# STM32U5F7 register map
File version: 1.1
CPU: CM33 r0p1, little endian, MPU, FPU, 4 interrupt priority bits
Registers are 32-bit, read-write, reset 0x0 unless marked. A register's access mark holds for its fields unless they carry their own. Offsets are from the block's base; [hi:lo] are bit positions; {n}, {i} and the like mark numbered series.

## LPDMA1
Base 0x46025000
Same registers: SEC_LPDMA1 0x56025000
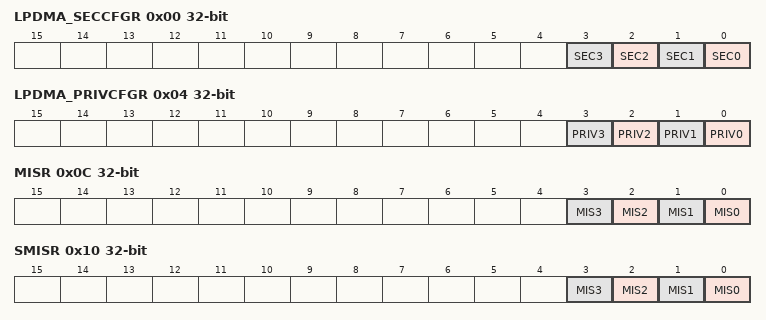
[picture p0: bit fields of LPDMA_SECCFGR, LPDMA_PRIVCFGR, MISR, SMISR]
0x00 LPDMA_SECCFGR — LPDMA secure configuration register
  [n] SEC{n} (n=0..3)
0x04 LPDMA_PRIVCFGR — LPDMA privileged configuration register
  [n] PRIV{n} (n=0..3)
0x0C MISR ro — LPDMA non-secure masked interrupt status register
  [n] MIS{n} (n=0..3)
0x10 SMISR ro — LPDMA secure masked interrupt status register
  [n] MIS{n} (n=0..3)
{0x50+0x80*i} LPDMA_C{i}LBAR (i=0..3) — channel x linked-list base address register
  [31:16] LBA — linked-list base address of DMA channel x
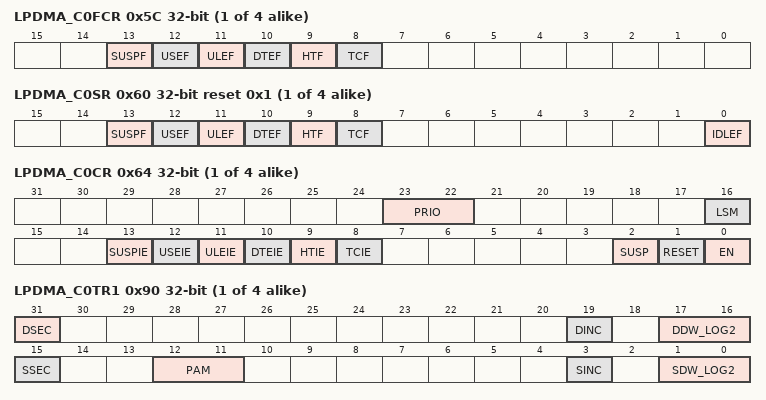
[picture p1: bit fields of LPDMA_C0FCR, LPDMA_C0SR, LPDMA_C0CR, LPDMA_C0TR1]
{0x5C+0x80*i} LPDMA_C{i}FCR wo (i=0..3) — LPDMA channel x flag clear register
  [13] SUSPF — completed suspension flag clear - 0: no effect - 1: clears the corresponding SUSPF flag
  [12] USEF — user setting error flag clear - 0: no effect - 1: clears the corresponding USEF flag
  [11] ULEF — update link transfer error flag clear - 0: no effect - 1: clears the corresponding ULEF flag
  [10] DTEF — data transfer error flag clear - 0: no effect - 1: clears the corresponding DTEF flag
  [9] HTF — half transfer flag clear - 0: no effect - 1: clears the corresponding HTF flag
  [8] TCF — transfer complete flag clear - 0: no effect - 1: clears the corresponding TCF flag
{0x60+0x80*i} LPDMA_C{i}SR ro reset 0x1 (i=0..3) — channel x status register
  [13] SUSPF — completed suspension flag - 0: no completed suspension event - 1: a completed suspension event occurred
  [12] USEF — user setting error flag - 0: no user setting error event - 1: a user setting error event occurred
  [11] ULEF — update link transfer error flag - 0: no update link transfer error event - 1: a master bus error event occurred while updating a linked-list register from memory
  [10] DTEF — data transfer error flag - 0: no data transfer error event - 1: a master bus error event occurred on a data transfer
  [9] HTF — half transfer flag - 0: no half transfer event - 1: an half transfer event occurred An half transfer event is either an half block transfer or an half 2D/repeated block transfer, depending on the transfer complete event mode i.e. LPDMA_CxTR2.TCEM[1:0]. An half block transfer occurs when half of the bytes of the source block size (i.e. rounded up integer of LPDMA_CxBR1.BNDT[15:0]/2) has been transferred to the destination. Half 2D/repeated block transfer occurs when half of the repeated blocks (i.e. rounded up integer of (LPDMA_CxBR1.BRC[10:0]+1)/2) have been transferred to the destination.
  [8] TCF — transfer complete flag - 0: no transfer complete event - 1: a transfer complete event occurred A transfer complete event is either a block transfer complete or a 2D/repeated block transfer complete, or a LLI transfer complete including the upload of the next LLI if any, or the full linked-list completion, depending on the transfer complete event mode i.e. LPDMA_CxTR2.TCEM[1:0].
  [0] IDLEF — idle flag - 0: the channel is not in idle state - 1: the channel is in idle state This idle flag is de-asserted by hardware when the channel is enabled (i.e. is written 1 into LPDMA_CxCR.EN) with a valid channel configuration (i.e. no USEF to be immediately reported). This idle flag is asserted after hard reset or by hardware when the channel is back in idle state (i.e. in suspended or disabled state).
{0x64+0x80*i} LPDMA_C{i}CR (i=0..3) — channel x control register
  [23:22] PRIO — priority level of the DMA transfer of the channel x vs others- 00: low priority, low weight- 01: low priority, mid weight- 10: low priority, high weight- 11: high priorityNote: This bit must be written when EN=0. This bit is read-only when EN=1.
  [16] LSM — Link Step mode:- 0: channel is executed for the full linked-list, and completed at the end (if any) of the last LLI i.e. when LPDMA_CxLLR=0: the 16 low significant bits of the link address are null (LA[15:0]=0) and all the update bits are null i.e. UT1=UB1=UT2=USA=UDA=UB2 =UT3=ULL=0. Then LPDMA_CxBR1.BRC[10:0]=0 and LPDMA_CxBR1.BNDT[15:0]=0.- 1: channel is executed once for the current LLI:* First the (possibly 2D/repeated) block transfer is executed as defined by the current internal register file until that (LPDMA_CxBR1.BRC[10:0]=0 and LPDMA_CxBR1.BNDT[15:0]=0).* Secondly the next linked-list data structure is conditionally uploaded from memory as defined by LPDMA_CxLLR register. Then channel execution is completed.Note: This bit must be written when EN=0. This bit is read-only when EN=1.
  [13] SUSPIE — completed suspension interrupt enable - 0: interrupt disabled - 1: interrupt enabled
  [12] USEIE — user setting error interrupt enable - 0: interrupt disabled - 1: interrupt enabled
  [11] ULEIE — update link transfer error interrupt enable - 0: interrupt disabled - 1: interrupt enabled
  [10] DTEIE — data transfer error interrupt enable - 0: interrupt disabled - 1: interrupt enabled
  [9] HTIE — half transfer complete interrupt enable - 0: interrupt disabled - 1: interrupt enabled
  [8] TCIE — transfer complete interrupt enable - 0: interrupt disabled - 1: interrupt enabled
  [2] SUSP — suspend - 0: write: resume channel, read: channel not suspended - 1: write: suspend channel, read: channel suspended Writing 1 into the field RESET (bit 1) causes the hardware to de-assert this bit, whatever is written into this bit 2. Else: Software must write 1 in order to suspend an active channel i.e. a channel with an on-going DMA transfer over its master ports. Software must write 0 in order to resume a suspended channel, following the programming sequence in Figure 3: DMA channel suspend and resume sequence.
  [1] RESET — reset - 0: no channel reset - 1: channel reset This bit is write only. Writing 0 has no impact. Writing 1 implies/will imply the reset of the FIFO, the reset of the channel internal state, and the reset of the SUSP and EN bits, whatever is written in respectively bit 2 and bit 0. The reset is/will be effective when the channel is in state i.e. either i) the active channel is in suspended state (i.e. LPDMA_CxSR.SUSPF=1 and LPDMA_CxSR.IDLEF=1 and LPDMA_CxCR.EN=1) or ii) the channel is in disabled state (i.e. LPDMA_CxSR.IDLEF=1 and LPDMA_CxCR.EN=0). After writing a RESET, if the user wants to continue using this channel, the user should explicitly reconfigure the channel including the hardware-modified configuration registers LPDMA_CxBR1, LPDMA_CxSAR and LPDMA_CxDAR, before enabling again the channel. Following the programming sequence in Figure 4: DMA channel abort and restart sequence.
  [0] EN — enable - 0: write: ignored, read: channel disabled - 1: write: enable channel, read: channel enabled Writing 1 into the field RESET (bit 1) causes the hardware to de-assert this bit, whatever is written into this bit 0. Else: * this bit is de-asserted by hardware when there is a transfer error (master bus error or user setting error) or when there is a channel transfer complete (channel ready to be configured, e.g. if LSM=1 at the end of a single execution of the LLI). * Else, this bit can be asserted by software. Writing 0 into this EN bit is ignored.
{0x90+0x80*i} LPDMA_C{i}TR1 (i=0..3) — LPDMA channel x transfer register 1
  [31] DSEC — security attribute of the DMA transfer to the destinationThis is a secure register bit.This bit can only be read by a secure software. This bit must be written by a secure software when LPDMA_SECCFGR.SECx=1. A secure write is ignored when LPDMA_SECCFGR.SECx=0.When is de-asserted LPDMA_SECCFGR.SECx, this bit is also de-asserted by hardware (on a secure reconfiguration of the channel as non-secure), and the DMA transfer to the destination is non-secure.If LPDMA_SECCFGR.SECx=1 (and a secure access):- 0: non-secure- 1: secure
  [19] DINC — destination incrementing burst- 0: fixed burst- 1: contiguously incremented burstThe destination address, pointed by DMA_CxDAR, is either kept constant after a burst beat/single transfer, or is incremented by the offset value corresponding to a contiguous data after a burst beat/single transfer.
  [17:16] DDW_LOG2 — binary logarithm of the destination data width of a burst, in bytes- 00: byte- 01: half-word (2 bytes)- 10: word (4 bytes)- 11: a user setting error is reported and no transfer is issued.Note: Setting a 8-byte data width is causing a user setting error to be reported and none transfer is issued.Note: A destination burst transfer must have an aligned address with its data width (c.f. start address LPDMA_CxDAR[2:0] and address offset LPDMA_CxTR3.DAO[2:0] vs DDW_LOG2[1:0]). Else a user setting error is reported and none transfer is issued.Note: When configured in packing mode (i.e. if PAM[1]=1 and destination data width different from source data width), a source block size must be a multiple of the destination data width (c.f. LPDMA_CxBR1.BNDT[2:0] vs DDW_LOG2[1:0]). Else a user setting error is reported and none transfer is issued.
  [15] SSEC — security attribute of the DMA transfer from the sourceThis is a secure register bit.This bit can only be read by a secure software. This bit must be written by a secure software when LPDMA_SECCFGR.SECx=1. A secure write is ignored when LPDMA_SECCFGR.SECx=0.When is de-asserted LPDMA_SECCFGR.SECx, this bit is also de-asserted by hardware (on a secure reconfiguration of the channel as non-secure), and the DMA transfer from the source is non-secure.If LPDMA_SECCFGR.SECx=1 (and a secure access):- 0: non-secure- 1: secure
  [12:11] PAM
  [3] SINC — source incrementing burst- 0: fixed burst- 1: contiguously incremented burstThe source address, pointed by DMA_CxSAR, is either kept constant after a burst beat/single transfer, or is incremented by the offset value corresponding to a contiguous data after a burst beat/single transfer.
  [1:0] SDW_LOG2 — binary logarithm of the source data width of a burst, in bytes- 00: byte- 01: half-word (2 bytes)- 10: word (4 bytes)- 11: a user setting error is reported and no transfer is issued.Note: Setting a 8-byte data width is causing a user setting error to be reported and none transfer is issued.Note: a source block size must be a multiple of the source data width (c.f. LPDMA_CxBR1.BNDT[2:0] vs SDW_LOG2[1:0]). Else a user setting error is reported and none transfer is issued.Note: A source burst transfer must have an aligned address with its data width (c.f. start address LPDMA_CxSAR[2:0] and address offset LPDMA_CxTR3.SAO[2:0] vs SDW_LOG2[1:0]). Else a user setting error is reported and none transfer is issued.
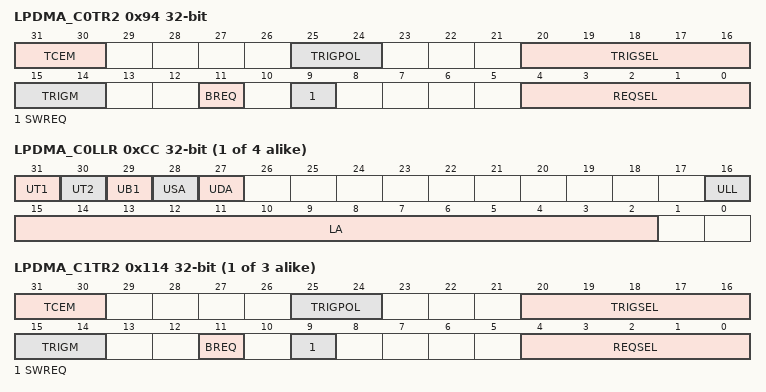
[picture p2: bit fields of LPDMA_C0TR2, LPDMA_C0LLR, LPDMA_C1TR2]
0x94 LPDMA_C0TR2 — LPDMA channel x transfer register 2
  [31:30] TCEM — Transfer complete event mode Defines the transfer granularity for the transfer complete (and half transfer complete) event generation. - 00: at block level (i.e. when LPDMA_CxBR1.BNDT[15:0]= 0): the complete (and the half) transfer event is generated at the (respectively half of the) end of a block. Note: If the initial LLI0 data transfer is null/void (i.e. directly programmed by the internal register file with LPDMA_CxBR1.BNDT[15:0]=0), then neither the complete transfer event nor the half transfer event is generated. - 01: channel x=0 to 11: same as 00 ;channel x=12 to 15: at 2D/repeated block level (i.e. when LPDMA_CxBR1.BRC[10:0]= 0 and LPDMA_CxBR1.BNDT[15:0]= 0): the complete (and the half) transfer event is generated at the end (respectively half of the end) of the 2D/repeated block Note: If the initial LLI0 data transfer is null/void (i.e. directly programmed by the internal register file with LPDMA_CxBR1.BNDT[15:0]=0), then neither the complete transfer event nor the half transfer event is generated. - 10: at LLI level: the complete transfer event is generated at the end of the LLI transfer, including the update of the LLI if any. The half transfer event is generated at the half of the LLI data transfer (the LLI data transfer being a block or a 2D/repeated block transfer), if any data transfer. Note: If the initial LLI0 data transfer is null/void (i.e. directly programmed by the internal register file with LPDMA_CxBR1.BNDT[15:0]=0), then the half transfer event is not generated, and the transfer complete event is generated when is completed the loading of the LLI1. - 11: at channel level: the complete transfer event is generated at the end of the last LLI transfer. The half transfer event is generated at the half of the data transfer of the last LLI. The last LLI is the one that updates the link address LPDMA_CxLLR.LA[15:2] to zero and that clears all the update bits - UT1, UT2, UB1, USA, UDA, if present UT3, UB2 and ULL - of the LPDMA_CxLLR register. If the channel transfer is continuous/infinite, no event is generated.
  [25:24] TRIGPOL — Trigger event polarity Defines the polarity of the selected trigger event input defined by TRIGSEL[5:0]. - 00: no trigger. Masked trigger event. - 01: trigger on the rising edge - 10: trigger on the falling edge - 11: same as 00
  [20:16] TRIGSEL — Trigger event input selection Note: Selects the trigger event input as per Table 13 of the DMA transfer, with an active trigger event if TRIGPOL[1:0] !=00.
  [15:14] TRIGM — Trigger mode: Defines the transfer granularity for its conditioning by the trigger. If the channel x is enabled (i.e. when LPDMA_CxCR.EN is asserted) with TRIGPOL[1:0]=00 or 11, these bits are ignored. Else, a DMA transfer is conditioned by (at least) one trigger hit, either at: - 00: at block level (for channel x=12 to 15: for each block if a 2D/repeated block is configured i.e. if LPDMA_CxBR1.BRC[10:0]! = 0): the first burst read of a/each block transfer is conditioned by one hit trigger. - 01: at 2D/repeated block level for channel x=12 to 15; same as 00 for channel x=0 to 11
  [11] BREQ
  [9] SWREQ — Software request When LPDMA_CxCR.EN is asserted, this field is internally taken into account: - 0: no software request. The selected hardware request REQSEL[6:0] is taken into account. - 1: software request (for a memory-to-memory transfer). And the default selected hardware request as per REQSEL[6:0] is ignored.
  [4:0] REQSEL — DMA hardware request selection If the channel x is activated (i.e. LPDMA_CxCR.EN is asserted) with SWREQ=1 (i.e. software request for a memory-to-memory transfer), this bit is ignored. Else, the selected hardware request as per Table 12 is internally taken into account. Note: The user must not assign a same input hardware request (i.e. a same REQSEL[6:0] value) to different active DMA channels (i.e. if LPDMA_CxCR.EN=1 and LPDMA_CxTR2.SWREQ=0 for the related x channels). In other words, DMA is not intended to hardware support the case of simultaneous enabled channels having been -incorrectly- configured with a same hardware peripheral request signal, and there is no user setting error reporting.
{0x98+0x80*i} LPDMA_C{i}BR1 (i=0..3) — LPDMA channel x block register 1
  [15:0] BNDT — block number of data bytes to transfer from the source
{0x9C+0x80*i} LPDMA_C{i}SAR (i=0..3) — LPDMA channel x source address register
  [31:0] SA — source address
{0xA0+0x80*i} LPDMA_C{i}DAR (i=0..3) — LPDMA channel x destination address register
  [31:0] DA — destination address
{0xCC+0x80*i} LPDMA_C{i}LLR (i=0..3) — LPDMA channel x linked-list address register
  [31] UT1 — Update LPDMA_CxTR1 from memory This bit controls the update of the LPDMA_CxTR1 register from the memory during the link transfer. - 0: no LPDMA_CxTR1 update - 1: LPDMA_CxTR1 update
  [30] UT2 — Update LPDMA_CxTR2 from memory This bit controls the update of the LPDMA_CxTR2 register from the memory during the link transfer. - 0: no LPDMA_CxTR2 update - 1: LPDMA_CxTR2 update
  [29] UB1 — Update LPDMA_CxBR1 from memory This bit controls the update of the LPDMA_CxBR1 register from the memory during the link transfer. If UB1=0 and if LPDMA_CxLLR != 0, the linked-list is not completed. Then LPDMA_CxBR1.BNDT[15:0] is restored to the programmed value after data transfer is completed and before the link transfer. - 0: no LPDMA_CxBR1 update (LPDMA_CxBR1.BNDT[15:0] is restored, if any link transfer) - 1: LPDMA_CxBR1 update
  [28] USA — Update LPDMA_CxSAR from memory This bit controls the update of the LPDMA_CxSAR register from the memory during the link transfer. - 0: no LPDMA_CxSAR update - 1: LPDMA_CxSAR update
  [27] UDA — Update LPDMA_CxDAR from memory This bit controls the update of the LPDMA_CxDAR register from the memory during the link transfer. - 0: no LPDMA_CxDAR update - 1: LPDMA_CxDAR update
  [16] ULL — Update LPDMA_CxLLR from memory This bit controls the update of the LPDMA_CxLLR register from the memory during the link transfer. - 0: no LPDMA_CxLLR update - 1: LPDMA_CxLLR update
  [15:2] LA — pointer (16-bit low significant address) to the next linked-list data structure If UT1=UT2=UB1=USA=UDA=ULL=0 and if LA[15:2]=0: the current LLI is the last one. The channel transfer is completed without any update of the linked-list DMA register file. Else, this field is the pointer to the memory address offset from which the next linked-list data structure will be automatically fetched from, once the data transfer is completed, in order to conditionally update the linked-list DMA internal register file i.e. possibly LPDMA_CxCTR1, LPDMA_CxTR2, LPDMA_CxBR1, LPDMA_CxSAR, LPDMA_CxDAR and LPDMA_CxLLR. Note: The user should program the pointer to be 32-bit aligned. The two low significant bits are write ignored.
{0x94+0x80*i} LPDMA_C{i}TR2 (i=1..3) — LPDMA channel x transfer register 2
  [31:30] TCEM — Transfer complete event mode Defines the transfer granularity for the transfer complete (and half transfer complete) event generation. - 00: at block level (i.e. when LPDMA_CxBR1.BNDT[15:0]= 0): the complete (and the half) transfer event is generated at the (respectively half of the) end of a block. Note: If the initial LLI0 data transfer is null/void (i.e. directly programmed by the internal register file with LPDMA_CxBR1.BNDT[15:0]=0), then neither the complete transfer event nor the half transfer event is generated. - 01: channel x=0 to 11: same as 00 ;channel x=12 to 15: at 2D/repeated block level (i.e. when LPDMA_CxBR1.BRC[10:0]= 0 and LPDMA_CxBR1.BNDT[15:0]= 0): the complete (and the half) transfer event is generated at the end (respectively half of the end) of the 2D/repeated block Note: If the initial LLI0 data transfer is null/void (i.e. directly programmed by the internal register file with LPDMA_CxBR1.BNDT[15:0]=0), then neither the complete transfer event nor the half transfer event is generated. - 10: at LLI level: the complete transfer event is generated at the end of the LLI transfer, including the update of the LLI if any. The half transfer event is generated at the half of the LLI data transfer (the LLI data transfer being a block or a 2D/repeated block transfer), if any data transfer. Note: If the initial LLI0 data transfer is null/void (i.e. directly programmed by the internal register file with LPDMA_CxBR1.BNDT[15:0]=0), then the half transfer event is not generated, and the transfer complete event is generated when is completed the loading of the LLI1. - 11: at channel level: the complete transfer event is generated at the end of the last LLI transfer. The half transfer event is generated at the half of the data transfer of the last LLI. The last LLI is the one that updates the link address LPDMA_CxLLR.LA[15:2] to zero and that clears all the update bits - UT1, UT2, UB1, USA, UDA, if present UT3, UB2 and ULL - of the LPDMA_CxLLR register. If the channel transfer is continuous/infinite, no event is generated.
  [25:24] TRIGPOL — Trigger event polarity Defines the polarity of the selected trigger event input defined by TRIGSEL[5:0]. - 00: no trigger. Masked trigger event. - 01: trigger on the rising edge - 10: trigger on the falling edge - 11: same as 00
  [20:16] TRIGSEL — Trigger event input selection Note: Selects the trigger event input as per Table 13 of the DMA transfer, with an active trigger event if TRIGPOL[1:0] !=00.
  [15:14] TRIGM — Trigger mode
  [11] BREQ
  [9] SWREQ — Software request When LPDMA_CxCR.EN is asserted, this field is internally taken into account: - 0: no software request. The selected hardware request REQSEL[6:0] is taken into account. - 1: software request (for a memory-to-memory transfer). And the default selected hardware request as per REQSEL[6:0] is ignored.
  [4:0] REQSEL — DMA hardware request selection If the channel x is activated (i.e. LPDMA_CxCR.EN is asserted) with SWREQ=1 (i.e. software request for a memory-to-memory transfer), this bit is ignored. Else, the selected hardware request as per Table 12 is internally taken into account. Note: The user must not assign a same input hardware request (i.e. a same REQSEL[6:0] value) to different active DMA channels (i.e. if LPDMA_CxCR.EN=1 and LPDMA_CxTR2.SWREQ=0 for the related x channels). In other words, DMA is not intended to hardware support the case of simultaneous enabled channels having been -incorrectly- configured with a same hardware peripheral request signal, and there is no user setting error reporting.
